VERSION ""

NS_ :

BS_:

BU_: AMS_Shield

BO_ 3221225472 VECTOR__INDEPENDENT_SIG_MSG: 0 Vector__XXX
 SG_ Simulink_BatSOC : 0|13@1+ (0.001,0) [0|8.191] "V" Vector__XXX
 SG_ Simulink_BatCurrent : 0|14@1+ (0.01,0) [0|163.83] "A" Vector__XXX

BO_ 34 New_Message_15: 8 AMS_Shield
 SG_ Voltage_Cell01 : 0|10@1+ (0.01,0) [0|10.23] "V" Vector__XXX

BO_ 512 AMS_Current: 8 AMS_Shield
 SG_ TS_Current : 0|18@1- (0.001,0) [-131.072|131.071] "A" Vector__XXX

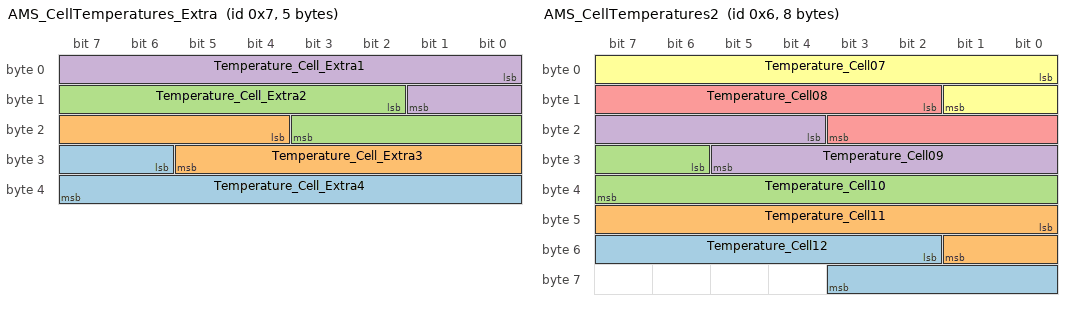
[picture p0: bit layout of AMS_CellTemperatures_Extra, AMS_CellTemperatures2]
BO_ 7 AMS_CellTemperatures_Extra: 5 AMS_Shield
 SG_ Temperature_Cell_Extra4 : 30|10@1+ (0.1,0) [0|102.3] "°C" Vector__XXX
 SG_ Temperature_Cell_Extra3 : 20|10@1+ (0.1,0) [0|102.3] "°C" Vector__XXX
 SG_ Temperature_Cell_Extra2 : 10|10@1+ (0.1,0) [0|102.3] "°C" Vector__XXX
 SG_ Temperature_Cell_Extra1 : 0|10@1+ (0.1,0) [0|102.3] "°C" Vector__XXX

BO_ 6 AMS_CellTemperatures2: 8 AMS_Shield
 SG_ Temperature_Cell12 : 50|10@1+ (0.1,0) [0|102.3] "°C" Vector__XXX
 SG_ Temperature_Cell11 : 40|10@1+ (0.1,0) [0|102.3] "°C" Vector__XXX
 SG_ Temperature_Cell10 : 30|10@1+ (0.1,0) [0|102.3] "°C" Vector__XXX
 SG_ Temperature_Cell09 : 20|10@1+ (0.1,0) [0|102.3] "°C" Vector__XXX
 SG_ Temperature_Cell08 : 10|10@1+ (0.1,0) [0|102.3] "°C" Vector__XXX
 SG_ Temperature_Cell07 : 0|10@1+ (0.1,0) [0|102.3] "°C" Vector__XXX

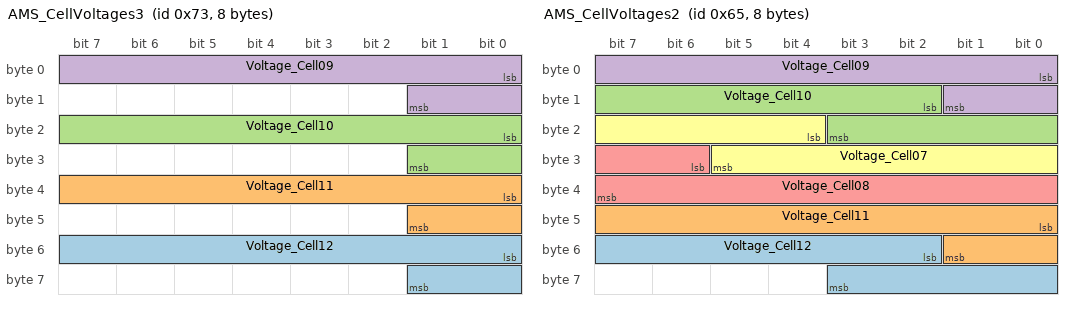
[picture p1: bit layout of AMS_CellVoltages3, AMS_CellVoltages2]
BO_ 115 AMS_CellVoltages3: 8 AMS_Shield
 SG_ Voltage_Cell12 : 48|10@1+ (0.01,0) [0|8.191] "V" Vector__XXX
 SG_ Voltage_Cell11 : 32|10@1+ (0.01,0) [0|8.191] "V" Vector__XXX
 SG_ Voltage_Cell10 : 16|10@1+ (0.01,0) [0|8.191] "V" Vector__XXX
 SG_ Voltage_Cell09 : 0|10@1+ (0.01,0) [0|8.191] "V" Vector__XXX

BO_ 101 AMS_CellVoltages2: 8 AMS_Shield
 SG_ Voltage_Cell12 : 50|10@1+ (0.01,0) [0|8.191] "V" Vector__XXX
 SG_ Voltage_Cell11 : 40|10@1+ (0.01,0) [0|8.191] "V" Vector__XXX
 SG_ Voltage_Cell10 : 10|10@1+ (0.01,0) [0|8.191] "V" Vector__XXX
 SG_ Voltage_Cell09 : 0|10@1+ (0.01,0) [0|8.191] "V" Vector__XXX
 SG_ Voltage_Cell08 : 30|10@1+ (0.01,0) [0|8.191] "V" Vector__XXX
 SG_ Voltage_Cell07 : 20|10@1+ (0.01,0) [0|8.191] "V" Vector__XXX

BO_ 1313 IVTS_Current: 6 Vector__XXX
 SG_ IVTS_Current : 23|32@0- (1,0) [-2147483648|2147483647] "mA"  AMS_Shield

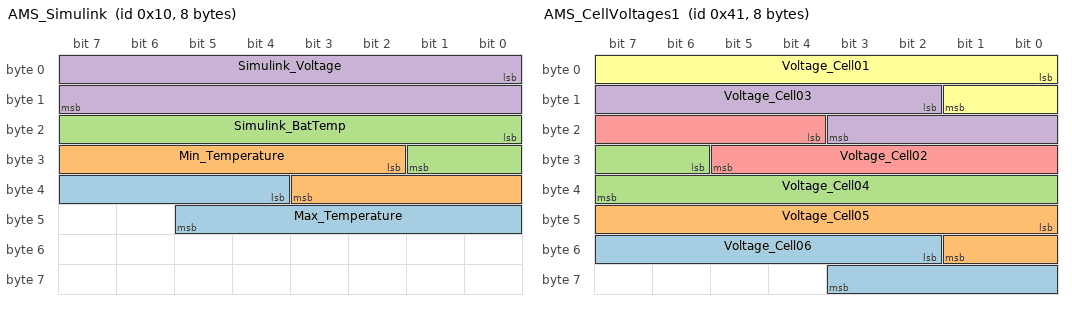
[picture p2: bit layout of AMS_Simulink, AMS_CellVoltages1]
BO_ 16 AMS_Simulink: 8 AMS_Shield
 SG_ Max_Temperature : 36|10@1+ (0.1,0) [0|102.3] "°C" Vector__XXX
 SG_ Min_Temperature : 26|10@1+ (0.1,0) [0|102.3] "°C" Vector__XXX
 SG_ Simulink_BatTemp : 16|10@1+ (0.1,0) [0|102.3] "°C" Vector__XXX
 SG_ Simulink_Voltage : 0|16@1+ (0.001,0) [0|65.535] "V" Vector__XXX

BO_ 48 AMS_Fault_Summary: 3 AMS_Shield
 SG_ Fault_System_S1_D2 : 22|1@1+ (1,0) [0|1] "" Vector__XXX
 SG_ Fault_System_S1_D1 : 14|1@1+ (1,0) [0|1] "" Vector__XXX
 SG_ Fault_Protection_S1_D2 : 16|1@1+ (1,0) [0|1] "" Vector__XXX
 SG_ Fault_Protection_S1_D1 : 8|1@1+ (1,0) [0|1] "" Vector__XXX
 SG_ Fault_Power_Rail_S1_D2 : 23|1@1+ (1,0) [0|1] "" Vector__XXX
 SG_ Fault_Power_Rail_S1_D1 : 15|1@1+ (1,0) [0|1] "" Vector__XXX
 SG_ Fault_OVOV_S1_D2 : 21|1@1+ (1,0) [0|1] "" Vector__XXX
 SG_ Fault_OVOV_S1_D1 : 13|1@1+ (1,0) [0|1] "" Vector__XXX
 SG_ Fault_OTUT_S1_D2 : 20|1@1+ (1,0) [0|1] "" Vector__XXX
 SG_ Fault_OTUT_S1_D1 : 12|1@1+ (1,0) [0|1] "" Vector__XXX
 SG_ Fault_OTP_S1_D2 : 18|1@1+ (1,0) [0|1] "" Vector__XXX
 SG_ Fault_OTP_S1_D1 : 10|1@1+ (1,0) [0|1] "" Vector__XXX
 SG_ Fault_Communication_S1_D2 : 19|1@1+ (1,0) [0|1] "" Vector__XXX
 SG_ Fault_Communication_S1_D1 : 11|1@1+ (1,0) [0|1] "" Vector__XXX
 SG_ Fault_ADC_Comparison_S1_D2 : 17|1@1+ (1,0) [0|1] "" Vector__XXX
 SG_ Fault_ADC_Comparison_S1_D1 : 9|1@1+ (1,0) [0|1] "" Vector__XXX
 SG_ Fault_Power_Rail_BD : 7|1@1+ (1,0) [0|1] "" Vector__XXX
 SG_ Fault_System_BD : 6|1@1+ (1,0) [0|1] "" Vector__XXX
 SG_ Fault_OVOV_BD : 5|1@1+ (1,0) [0|1] "" Vector__XXX
 SG_ Fault_OTUT_BD : 4|1@1+ (1,0) [0|1] "" Vector__XXX
 SG_ Fault_Communication_BD : 3|1@1+ (1,0) [0|1] "" Vector__XXX
 SG_ Fault_OTP_BD : 2|1@1+ (1,0) [0|1] "" Vector__XXX
 SG_ Fault_ADC_Comparison_BD : 1|1@1+ (1,0) [0|1] "" Vector__XXX
 SG_ Fault_Protection_BD : 0|1@1+ (1,0) [0|1] "" Vector__XXX

BO_ 65 AMS_CellVoltages1: 8 AMS_Shield
 SG_ Voltage_Cell06 : 50|10@1+ (0.01,0) [0|8.191] "V" Vector__XXX
 SG_ Voltage_Cell05 : 40|10@1+ (0.01,0) [0|10.23] "V" Vector__XXX
 SG_ Voltage_Cell04 : 30|10@1+ (0.01,0) [0|8.191] "V" Vector__XXX
 SG_ Voltage_Cell03 : 10|10@1+ (0.01,0) [0|10.23] "V" Vector__XXX
 SG_ Voltage_Cell02 : 20|10@1+ (0.01,0) [0|10.23] "V" Vector__XXX
 SG_ Voltage_Cell01 : 0|10@1+ (0.01,0) [0|10.23] "V" Vector__XXX

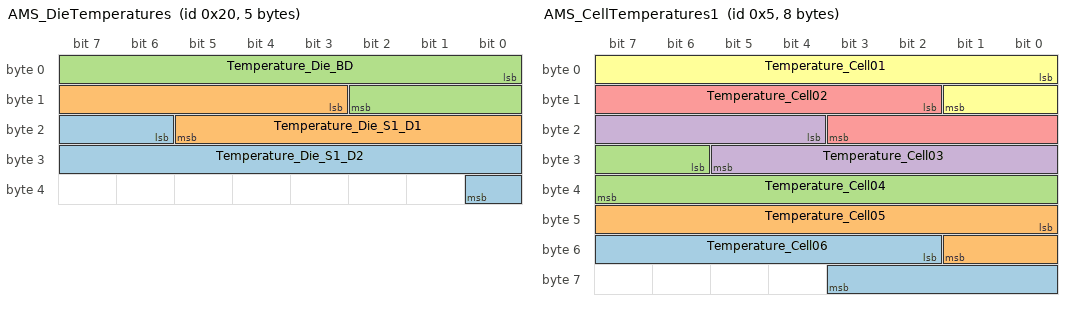
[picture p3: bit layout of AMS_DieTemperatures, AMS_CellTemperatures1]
BO_ 32 AMS_DieTemperatures: 5 AMS_Shield
 SG_ Temperature_Die_S1_D2 : 22|11@1+ (0.1,0) [0|204.7] "°C" Vector__XXX
 SG_ Temperature_Die_S1_D1 : 11|11@1+ (0.1,0) [0|204.7] "°C" Vector__XXX
 SG_ Temperature_Die_BD : 0|11@1+ (0.1,0) [0|204.7] "°C" Vector__XXX

BO_ 5 AMS_CellTemperatures1: 8 AMS_Shield
 SG_ Temperature_Cell06 : 50|10@1+ (0.1,0) [0|102.3] "°C" Vector__XXX
 SG_ Temperature_Cell05 : 40|10@1+ (0.1,0) [0|102.3] "°C" Vector__XXX
 SG_ Temperature_Cell04 : 30|10@1+ (0.1,0) [0|102.3] "°C" Vector__XXX
 SG_ Temperature_Cell03 : 20|10@1+ (0.1,0) [0|102.3] "°C" Vector__XXX
 SG_ Temperature_Cell02 : 10|10@1+ (0.1,0) [0|102.3] "°C" Vector__XXX
 SG_ Temperature_Cell01 : 0|10@1+ (0.1,0) [0|102.3] "°C" Vector__XXX

CM_ BO_ 3221225472 "This is a message for not used signals, created by Vector CANdb++ DBC OLE DB Provider.";
BA_DEF_  "BusType" STRING ;
BA_DEF_ SG_  "GenSigSendType" ENUM  "Cyclic","OnWrite","OnWriteWithRepetition","OnChange","OnChangeWithRepetition","IfActive","IfActiveWithRepetition","NoSigSendType";
BA_DEF_ BO_  "GenMsgSendType" ENUM  "Cyclic","not_used","not_used","not_used","not_used","Cyclic","not_used","IfActive","NoMsgSendType";
BA_DEF_ BO_  "GenMsgCycleTime" INT 0 0;
BA_DEF_DEF_  "BusType" "";
BA_DEF_DEF_  "GenSigSendType" "Cyclic";
BA_DEF_DEF_  "GenMsgSendType" "NoMsgSendType";
BA_DEF_DEF_  "GenMsgCycleTime" 0;
BA_ "GenMsgCycleTime" BO_ 34 50;
BA_ "GenMsgCycleTime" BO_ 512 50;
BA_ "GenMsgCycleTime" BO_ 7 50;
BA_ "GenMsgCycleTime" BO_ 6 50;
BA_ "GenMsgCycleTime" BO_ 115 50;
BA_ "GenMsgCycleTime" BO_ 101 50;
BA_ "GenMsgCycleTime" BO_ 1313 20;
BA_ "GenMsgCycleTime" BO_ 16 50;
BA_ "GenMsgCycleTime" BO_ 48 50;
BA_ "GenMsgCycleTime" BO_ 65 50;
BA_ "GenMsgCycleTime" BO_ 32 50;
BA_ "GenMsgCycleTime" BO_ 5 50;
